# PAC55XX register map
Vendor: Qorvo, Inc.; Series: PAC55XX; File version: 1.0
CPU: CM4 r0p1, little endian, MPU, FPU, vendor SysTick, 3 interrupt priority bits
Registers are 32-bit, read-write, reset 0x0 unless marked. A register's access mark holds for its fields unless they carry their own. Offsets are from the block's base; [hi:lo] are bit positions.

## CAN — Controller Area Network
Base 0x400A0000
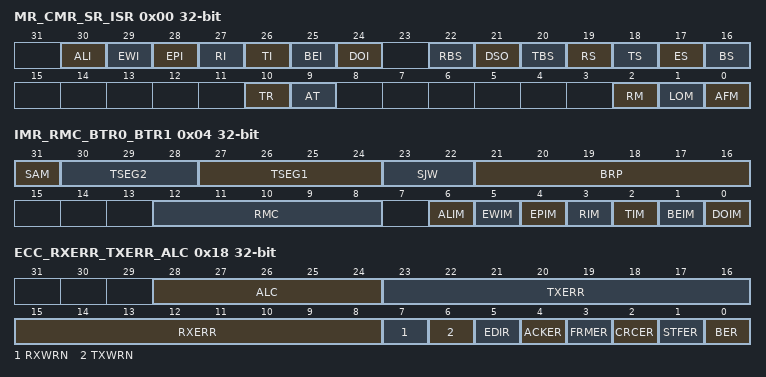
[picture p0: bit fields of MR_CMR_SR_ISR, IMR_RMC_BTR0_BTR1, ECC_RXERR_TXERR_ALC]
0x00 MR_CMR_SR_ISR — CAN Mode Register/Command Register/Status Register/Interrupt Status or ACK Register
  [30] ALI — Arbitration Lost Interrupt
  [29] EWI — Error Warning Interrupt
  [28] EPI — Error Passive Interrupt
  [27] RI — Receive Interrupt
  [26] TI — Transmit Interrupt
  [25] BEI — Bus Error Interrupt
  [24] DOI — Data Overrun Interrupt
  [22] RBS ro — Receive Buffer Status
  [21] DSO ro — Data Overrun Status
  [20] TBS ro — Transmit Buffer Status
  [19] RS ro — Receive Status
  [18] TS ro — Transmit Status
  [17] ES ro — Error Status
  [16] BS ro — Bus Off Status
  [10] TR — Transmit request
  [9] AT — Abort Transmission
  [2] RM — Reset mode
  [1] LOM — Listen-only mode
  [0] AFM — Hardware filter acceptance scheme
    0=DUAL (Dual filter); 1=SINGLE (Single filter)
0x04 IMR_RMC_BTR0_BTR1 — CAN Interrupt Mask Register/Receive Message Counter Register/Bus Timing 0 Register/Bus Timing 1 Register
  [31] SAM — Number of bus level samples
    0=ONE (One sample); 1=THREE (Three samples)
  [30:28] TSEG2 — Number of clock cycles per Time segment 2
  [27:24] TSEG1 — Number of clock cycles per Time segment 1
  [23:22] SJW — Synchronization jump width
  [21:16] BRP — Baud rate prescaler
  [12:8] RMC ro — Number of frames stored in the receive FIFO
  [6] ALIM — Arbitration Lost Interrupt Mask
  [5] EWIM — Error Warning Interrupt Mask
  [4] EPIM — Error Passive Interrupt Mask
  [3] RIM — Receive Interrupt Mask
  [2] TIM — Transmit Interrupt Mask
  [1] BEIM — Bus Error Interrupt Mask
  [0] DOIM — Data Overrun Interrupt Mask
0x08 TXBUF — CAN Transmit Buffer register
  [31:0] TXBUF — Transmit buffer data
0x0C RXBUF — CAN Receive Buffer register
  [31:0] RXBUF ro — Receive buffer data
0x10 ACR — CAN Acceptance Code register
  [31:0] ACR — Acceptance code
0x14 AMR — CAN Acceptance Mask register
  [31:0] AMR — Acceptance code mask
0x18 ECC_RXERR_TXERR_ALC ro — CAN Error Code Capture register/Receive Error Counter Register/Transmit Error Counter Register/Arbitration Lost Code Capture Register
  [28:24] ALC — Arbitration lost capture
    0=ID28_10 (Arbitration lost in ID28/10); 1=ID28_9 (Arbitration lost in ID28/9); 2=ID28_8 (Arbitration lost in ID28/8); 3=ID28_7 (Arbitration lost in ID28/7); 4=ID28_6 (Arbitration lost in ID28/6); 5=ID28_5 (Arbitration lost in ID28/5); 6=ID28_4 (Arbitration lost in ID28/4); 7=ID28_3 (Arbitration lost in ID28/3); 8=ID28_2 (Arbitration lost in ID28/2); 9=ID28_1 (Arbitration lost in ID28/1); 10=ID28_0 (Arbitration lost in ID28/0); 11=SRR_RTR (Arbitration lost in SRR/RTR); 12=IDE (Arbitration lost in IDE bit); 13=ID_17_24 (Arbitration lost in ID17^24); 14=ID_16_14 (Arbitration lost in ID16^24); 15=ID_15_24 (Arbitration lost in ID15^24); 16=ID_14_24 (Arbitration lost in ID14^24); 17=ID_13_24 (Arbitration lost in ID13^24); 18=ID_12_24 (Arbitration lost in ID12^24); 19=ID_11_24 (Arbitration lost in ID11^24); 20=ID_10_24 (Arbitration lost in ID10^24); 21=ID_9_24 (Arbitration lost in ID9^24); 22=ID_8_24 (Arbitration lost in ID8^24); 23=ID_7_24 (Arbitration lost in ID7^24); 24=ID_6_24 (Arbitration lost in ID6^24); 25=ID_5_24 (Arbitration lost in ID5^24); 26=ID_4_24 (Arbitration lost in ID4^24); 27=ID_3_24 (Arbitration lost in ID3^24); 28=ID_2_24 (Arbitration lost in ID2^24); 29=ID_1_24 (Arbitration lost in ID1^24); 30=ID_0_24 (Arbitration lost in ID0^24); 31=RTR (Arbitration lost in RTR)
  [23:16] TXERR — Transmit error counter
  [15:8] RXERR — Receive error counter
  [7] RXWRN — Set when CANRXERR is major or equal to 96
  [6] TXWRN — Set when CANTXERR is major or equal to 96
  [5] EDIR — Direction of transfer while error occurred
    0=TX (Transmission); 1=RX (Reception)
  [4] ACKER — Acknowledge error occurred
  [3] FRMER — Form error occurred
  [2] CRCER — CRC error occurred
  [1] STFER — Stuff error occurred
  [0] BER — Bit error occurred
